# CY8C5888LTI_LP097 register map
File version: 0.1
CY8C58LP
Registers are 8-bit, read-write, no defined reset value unless marked. A register's access mark holds for its fields unless they carry their own. Offsets are from the block's base; lines under a group give offsets from that group; [hi:lo] are bit positions; {n}, {i} and the like mark numbered series; 'fields as' and 'values as' point back to an identical list; <NAME> marks a mode.

## Memory map
0x00000000 ClockCounter
0x00000000 ConsolePort_1_ClockTimer
0x00000000 ConsolePort_1_WinTimer
0x00000000 USBUART — USBFS
0x00000000 ConsolePort_2_ClockTimer
0x00000000 ConsolePort_2_WinTimer
0x40006470 Vis_L
0x40006472 Vis_L_2
0x40006474 Vis_H_1
0x40006476 Vis_H_3
0x40006477 Vis_H_2
0x40006478 Vis_H
0x4000647A ClockCountSel
0x40006577 Vis_L_1
0x40006578 Vis_L_3

## ClockCountSel
Base 0x4000647A
0x00 ClockCountSel_CONTROL_REG

## Vis_L_2
Base 0x40006472
Registers as ClockCountSel (with ClockCountSel read as Vis_L_2).

## Vis_H_3
Base 0x40006476
Registers as ClockCountSel (with ClockCountSel read as Vis_H_3).

## Vis_L_3
Base 0x40006578
Registers as ClockCountSel (with ClockCountSel read as Vis_L_3).

## Vis_H_2
Base 0x40006477
Registers as ClockCountSel (with ClockCountSel read as Vis_H_2).

## Vis_H_1
Base 0x40006474
Registers as ClockCountSel (with ClockCountSel read as Vis_H_1).

## Vis_H
Base 0x40006478
Registers as ClockCountSel (with ClockCountSel read as Vis_H).

## Vis_L
Base 0x40006470
Registers as ClockCountSel (with ClockCountSel read as Vis_L).

## Vis_L_1
Base 0x40006577
Registers as ClockCountSel (with ClockCountSel read as Vis_L_1).

## ClockCounter
Base 0x00000000
0x40006507 ClockCounter_COUNTER — UDB.A0 - Current Counter Value
0x40006527 ClockCounter_PERIOD — UDB.D0 - Assigned Period
0x40006537 ClockCounter_COMPARE — UDB.D1 - Assigned Compare Value
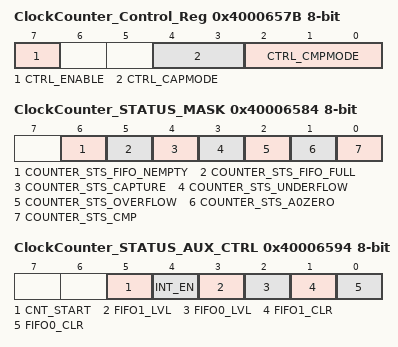
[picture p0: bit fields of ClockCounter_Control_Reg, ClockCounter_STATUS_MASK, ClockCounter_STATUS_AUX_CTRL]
0x4000657B ClockCounter_Control_Reg — UDB Control Register - Assigned Control Register Value
  [7] CTRL_ENABLE — Enable Counter
  [4:3] CTRL_CAPMODE — Capture mode
  [2:0] CTRL_CMPMODE — Compare mode
0x40006584 ClockCounter_STATUS_MASK — UDB Status bits Interrupt Mask Enable Register
  [6] COUNTER_STS_FIFO_NEMPTY — FIFO Not Empty Status
  [5] COUNTER_STS_FIFO_FULL — FIFO Full Status
  [4] COUNTER_STS_CAPTURE — Capture Status
  [3] COUNTER_STS_UNDERFLOW — Underflow status
  [2] COUNTER_STS_OVERFLOW — Overflow status
  [1] COUNTER_STS_A0ZERO — A0 Zero ouput status
  [0] COUNTER_STS_CMP — Compare output status
0x40006594 ClockCounter_STATUS_AUX_CTRL — UDB Auxilliary Control Register
  [5] CNT_START — FIFO0 clear
    0=E_CNT_START0 (Disable counter); 1=E_CNT_START1 (Enable counter)
  [4] INT_EN
    0=E_INT_EN0 (Interrupt disabled); 1=E_INT_EN1 (Interrupt enabled)
  [3] FIFO1_LVL — FIFO level
    0=E_FIFO_LVL_0 (FIFO LVL: input mode: FIFO not full; output mode: FIFO not empty); 1=E_FIFO_LVL_1 (FIFO LVL: input mode: FIFO at least 1/2 empty; output mode: FIFO at least 1/2 full)
  [2] FIFO0_LVL — FIFO level
    values as FIFO1_LVL
  [1] FIFO1_CLR — FIFO1 clear
    0=E_FIFO_CLR_0 (Normal FIFO operation); 1=E_FIFO_CLR_1 (Clear FIFO state)
  [0] FIFO0_CLR — FIFO0 clear
    values as FIFO1_CLR

## ConsolePort_1_ClockTimer
Base 0x00000000
0x4000650A ConsolePort_1_ClockTimer_COUNTER — UDB.A0 - Current Down Counter Value
0x4000652A ConsolePort_1_ClockTimer_PERIOD — UDB.D0 - Assigned Period
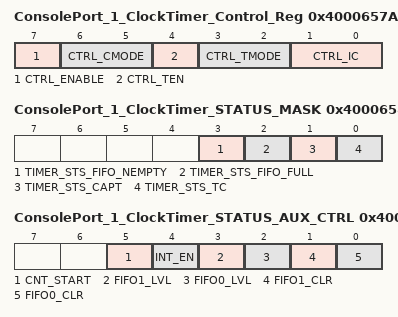
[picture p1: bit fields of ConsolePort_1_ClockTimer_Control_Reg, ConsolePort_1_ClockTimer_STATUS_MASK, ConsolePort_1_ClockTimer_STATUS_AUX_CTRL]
0x4000657A ConsolePort_1_ClockTimer_Control_Reg — UDB Control Register - Assigned Control Register Value
  [7] CTRL_ENABLE — Enable the Timer
  [6:5] CTRL_CMODE — Capture Mode
  [4] CTRL_TEN — Trigger Enable Bit
  [3:2] CTRL_TMODE — Trigger Mode
  [1:0] CTRL_IC — Interrupt Count
0x4000658A ConsolePort_1_ClockTimer_STATUS_MASK — UDB Status bits Interrupt Mask Enable Register
  [3] TIMER_STS_FIFO_NEMPTY ro — FIFO Empty status
  [2] TIMER_STS_FIFO_FULL ro — FIFO Full Status
  [1] TIMER_STS_CAPT ro — Enables the Interrupt on Capture
  [0] TIMER_STS_TC ro — Enables the Interrupt on TC
0x4000659A ConsolePort_1_ClockTimer_STATUS_AUX_CTRL — UDB Auxilliary Control Register
  [5] CNT_START — FIFO0 clear
    0=E_CNT_START0 (Disable counter); 1=E_CNT_START1 (Enable counter)
  [4] INT_EN
    0=E_INT_EN0 (Interrupt disabled); 1=E_INT_EN1 (Interrupt enabled)
  [3] FIFO1_LVL — FIFO level
    0=E_FIFO_LVL_0 (FIFO LVL: input mode: FIFO not full; output mode: FIFO not empty); 1=E_FIFO_LVL_1 (FIFO LVL: input mode: FIFO at least 1/2 empty; output mode: FIFO at least 1/2 full)
  [2] FIFO0_LVL — FIFO level
    values as FIFO1_LVL
  [1] FIFO1_CLR — FIFO1 clear
    0=E_FIFO_CLR_0 (Normal FIFO operation); 1=E_FIFO_CLR_1 (Clear FIFO state)
  [0] FIFO0_CLR — FIFO0 clear
    values as FIFO1_CLR
